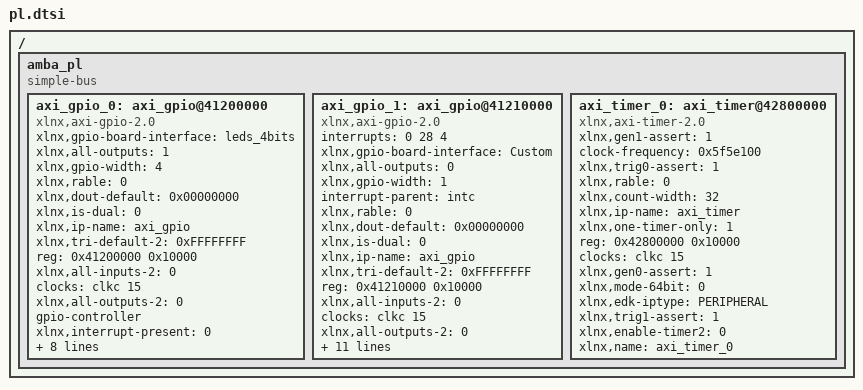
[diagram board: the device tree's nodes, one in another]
/ {
	amba_pl: amba_pl {
		ranges;
		compatible = "simple-bus";
		#address-cells = <1>;
		#size-cells = <1>;
		axi_gpio_0: axi_gpio@41200000 {
			xlnx,gpio-board-interface = "leds_4bits";
			compatible = "xlnx,axi-gpio-2.0" , "xlnx,xps-gpio-1.00.a";
			xlnx,all-outputs = <1>;
			#gpio-cells = <2>;
			xlnx,gpio-width = <4>;
			xlnx,rable = <0>;
			xlnx,dout-default = <0x00000000>;
			xlnx,is-dual = <0>;
			xlnx,ip-name = "axi_gpio";
			xlnx,tri-default-2 = <0xFFFFFFFF>;
			reg = <0x41200000 0x10000>;
			xlnx,all-inputs-2 = <0>;
			clocks = <&clkc 15>;
			xlnx,all-outputs-2 = <0>;
			gpio-controller;
			xlnx,interrupt-present = <0>;
			xlnx,gpio2-board-interface = "Custom";
			xlnx,edk-iptype = "PERIPHERAL";
			xlnx,dout-default-2 = <0x00000000>;
			xlnx,gpio2-width = <32>;
			status = "okay";
			clock-names = "s_axi_aclk";
			xlnx,use-board-flow;
			xlnx,tri-default = <0xFFFFFFFF>;
			xlnx,name = "axi_gpio_0";
			xlnx,all-inputs = <0>;
		};
		axi_gpio_1: axi_gpio@41210000 {
			#interrupt-cells = <2>;
			interrupts = < 0 28 4 >;
			xlnx,gpio-board-interface = "Custom";
			compatible = "xlnx,axi-gpio-2.0" , "xlnx,xps-gpio-1.00.a";
			xlnx,all-outputs = <0>;
			#gpio-cells = <2>;
			xlnx,gpio-width = <1>;
			interrupt-parent = <&intc>;
			xlnx,rable = <0>;
			xlnx,dout-default = <0x00000000>;
			xlnx,is-dual = <0>;
			xlnx,ip-name = "axi_gpio";
			xlnx,tri-default-2 = <0xFFFFFFFF>;
			reg = <0x41210000 0x10000>;
			xlnx,all-inputs-2 = <0>;
			clocks = <&clkc 15>;
			xlnx,all-outputs-2 = <0>;
			gpio-controller;
			xlnx,interrupt-present = <1>;
			xlnx,gpio2-board-interface = "Custom";
			xlnx,edk-iptype = "PERIPHERAL";
			xlnx,dout-default-2 = <0x00000000>;
			xlnx,gpio2-width = <32>;
			status = "okay";
			clock-names = "s_axi_aclk";
			xlnx,use-board-flow;
			interrupt-controller;
			interrupt-names = "ip2intc_irpt";
			xlnx,tri-default = <0xFFFFFFFF>;
			xlnx,name = "axi_gpio_1";
			xlnx,all-inputs = <1>;
		};
		axi_timer_0: axi_timer@42800000 {
			compatible = "xlnx,axi-timer-2.0" , "xlnx,xps-timer-1.00.a";
			xlnx,gen1-assert = <1>;
			clock-frequency = <0x5f5e100>;
			xlnx,trig0-assert = <1>;
			xlnx,rable = <0>;
			xlnx,count-width = <32>;
			xlnx,ip-name = "axi_timer";
			xlnx,one-timer-only = <1>;
			reg = <0x42800000 0x10000>;
			clocks = <&clkc 15>;
			xlnx,gen0-assert = <1>;
			xlnx,mode-64bit = <0>;
			xlnx,edk-iptype = "PERIPHERAL";
			xlnx,trig1-assert = <1>;
			status = "okay";
			clock-names = "s_axi_aclk";
			xlnx,enable-timer2 = <0>;
			xlnx,name = "axi_timer_0";
		};
	};
};
